# STM32U083 register map
File version: 0.2
CPU: CM0+ r0p1, little endian, MPU, no FPU, 4 interrupt priority bits
Registers are 32-bit, read-write, reset 0x0 unless marked. A register's access mark holds for its fields unless they carry their own. Offsets are from the block's base; [hi:lo] are bit positions; {n}, {i} and the like mark numbered series; 'fields as' and 'values as' point back to an identical list.

## AES — AES register block
Base 0x40026000
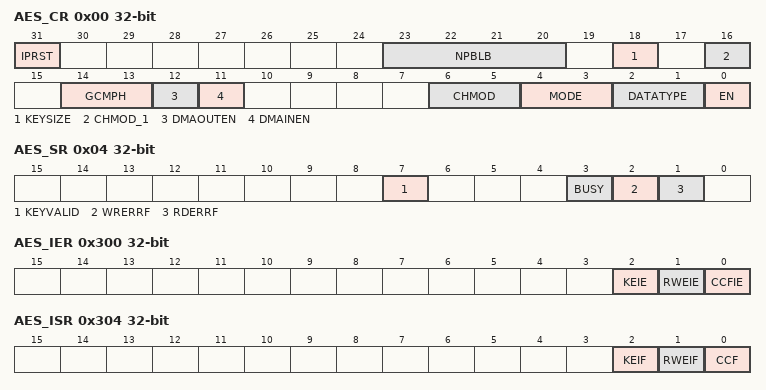
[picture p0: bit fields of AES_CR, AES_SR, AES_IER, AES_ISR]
0x00 AES_CR — AES control register
  [31] IPRST — AES peripheral software reset Setting the bit resets the AES peripheral, putting all registers to their default values, except the IPRST bit itself. Hence, any key-relative data are lost. For this reason, it is recommended to set the bit before handing over the AES to a less secure application. The bit must be kept low while writing any configuration registers.
  [23:20] NPBLB — Number of padding bytes in last block This padding information must be filled by software before processing the last block of GCM payload encryption or CCM payload decryption, otherwise authentication tag computation is incorrect. ...
    0=All bytes are valid (no padding); 1=Padding for the last LSB byte; 15=Padding for the 15 LSB bytes of last block
  [18] KEYSIZE — Key size selection This bitfield defines the key length in bits of the key used by AES. Attempts to write the bit are ignored when the EN is set before the write access and it is not cleared by that write access.
    0=128-bit; 1=256-bit
  [16] CHMOD_1 — CHMOD[2]
  [14:13] GCMPH — GCM or CCM phase selection This bitfield selects the phase, applicable only with GCM, GMAC or CCM chaining modes.
    0=Initialization phase; 1=Header phase; 2=Payload phase; 3=Final phase
  [12] DMAOUTEN — DMA output enable This bit enables automatic generation of DMA requests during the data phase, for outgoing data transfers from AES via DMA. Setting this bit is ignored when MODE[1:0] is at 0x1 (key derivation).
    0=Disable; 1=Enable
  [11] DMAINEN — DMA input enable This bit enables automatic generation of DMA requests during the data phase, for incoming data transfers to AES via DMA. Setting this bit is ignored when MODE[1:0] is at 0x1 (key derivation).
    0=Disable; 1=Enable
  [6:5] CHMOD — CHMOD[1:0]: Chaining mode This bitfield selects the AES chaining mode: others: Reserved Attempts to write the bitfield are ignored when EN is set before the write access and it is not cleared by that write access.
    0=Electronic codebook (ECB); 1=Cipher-block chaining (CBC); 2=Counter mode (CTR); 3=Galois counter mode (GCM) and Galois message authentication code (GMAC)
  [4:3] MODE — Operating mode This bitfield selects the AES operating mode: Attempts to write the bitfield are ignored when EN is set before the write access and it is not cleared by that write access.
    0=Encryption; 1=Key derivation (or key preparation), for ECB/CBC decryption only; 2=Decryption
  [2:1] DATATYPE — Data type This bitfield defines the format of data written in the AES_DINR register or read from the AES_DOUTR register, through selecting the mode of data swapping. This swapping is defined in Section121.4.14: AES data registers and data swapping. Attempts to write the bitfield are ignored when EN is set before the write access and it is not cleared by that write access.
    0=No swapping (32-bit data); 1=Half-word swapping (16-bit data); 2=Byte swapping (8-bit data); 3=Bit-level swapping
  [0] EN — Enable This bit enables/disables the AES peripheral. At any moment, clearing then setting the bit re-initializes the AES peripheral. This bit is automatically cleared by hardware upon the completion of the key preparation (MODE[1:0] at 0x1) and upon the completion of GCM/GMAC/CCM initialization phase. The bit cannot be set as long as KEYVALID1is cleared
    0=Disable; 1=Enable
0x04 AES_SR ro — AES status register
  [7] KEYVALID — Key valid flag This bit is set by hardware when the key of size defined by KEYSIZE is loaded in AES_KEYRx key registers. The EN bit can only be set when KEYVALID is set. The key must be written in the key registers in the correct sequence, otherwise the KEIF flag is set and KEYVALID remains cleared. If set, KEIF must be cleared through the AES_ICR register, otherwise KEYVALID cannot be set. See the KEIF flag description for more details. For further information on key loading, refer to Section121.4.15: AES key registers.
    0=Key not valid; 1=Key valid
  [3] BUSY — Busy This flag indicates whether AES is idle or busy. AES is flagged as idle when disabled (when EN is low) or when the last processing is completed. AES is flagged as busy when processing a block data, preparing a key (ECB or CBC decryption only). When GCM encryption is selected, this flag must be at zero before suspending current process to manage a higher-priority message.
    0=Idle; 1=Busy
  [2] WRERRF — Write error flag This bit is set when an unexpected write to the AES_DINR register occurred. When set WRERRF bit has no impact on the AES operations. The flag setting generates an interrupt if the RWEIE bit of the AES_IER register is set. The flag is cleared by setting the RWEIF bit of the AES_ICR register.
    0=No error; 1=Unexpected write to AES_DINR register occurred during computation or data output phase
  [1] RDERRF — Read error flag This bit is set when an unexpected read to the AES_DOUTR register occurred. When set RDERRF bit has no impact on the AES operations. The flag setting generates an interrupt if the RWEIE bit of the AES_IER register is set. The flag is cleared by setting the RWEIF bit of the AES_ICR register.
    0=No error; 1=Unexpected read to AES_DOUTR register occurred during computation or data input phase
0x08 AES_DINR wo — AES data input register
  [31:0] DIN — Data input A four-fold sequential write to this bitfield during the Input phase results in writing a complete 16-bytes block of input data to the AES peripheral. From the first to the fourth write, the corresponding data weights are [127:96], [95:64], [63:32], and [31:0]. Upon each write, the data from the 32-bit input buffer are handled by the data swap block according to the DATATYPE[1:0] bitfield, then written into the AES core 16-bytes input buffer. Reads return zero.
0x0C AES_DOUTR ro — AES data output register
  [31:0] DOUT — Data output This read-only bitfield fetches a 32-bit output buffer. A four-fold sequential read of this bitfield, upon the computation completion (CCF flag set), virtually reads a complete 16-byte block of output data from the AES peripheral. Before reaching the output buffer, the data produced by the AES core are handled by the data swap block according to the DATATYPE[1:0] bitfield. Data weights from the first to the fourth read operation are: [127:96], [95:64], [63:32], and [31:0].
0x10 AES_KEYR0 wo — AES key register 0
  [31:0] KEY — Cryptographic key, bits [31:0] These are bits [31:0] of the write-only bitfield KEY[255:0] AES encryption or decryption key, depending on the MODE[1:0] bitfield of the AES_CR register. Writes to AES_KEYRx registers are ignored when AES is enabled (EN bit set). A special writing sequence is required. In this sequence, any valid write to AES_KEYRx register clears the KEYVALID flag except for the sequence-completing write that sets it. Also refer to the description of the KEYVALID flag in the AES_SR register.
{0x10+4i} AES_KEYR{i} wo (i=1..3) — AES key register {i}
  [31:0] KEY — Cryptographic key, bits [{32i+31}:{32i}] Refer to the AES_KEYR0 register for description of the KEY[255:0] bitfield and for information relative to writing AES_KEYRx registers.
0x20 AES_IVR0 — AES initialization vector register 0
  [31:0] IVI — Initialization vector input, bits [31:0] AES_IVRx registers store the 128-bit initialization vector or the nonce, depending on the chaining mode selected. This value is updated by hardware after each computation round (when applicable). Write to this register is ignored when EN bit is set in AES_SR register
{0x20+4i} AES_IVR{i} (i=1..3) — AES initialization vector register {i}
  [31:0] IVI — Initialization vector input, bits [{32i+31}:{32i}] Refer to the AES_IVR0 register for description of the IVI[128:0] bitfield.
{0x20+4i} AES_KEYR{i} wo (i=4..7) — AES key register {i}
  fields as AES_KEYR1
{0x40+4i} AES_SUSPR{i} (i=0..7) — AES suspend registers
  [31:0] SUSP — Suspend data AES_SUSPRx registers contain the complete internal register states of the AES when the GCM, GMAC or CCM processing of the current task is suspended to process a higher-priority task. Refer to Section121.4.8: AES suspend and resume operations for more details. Read to this register returns zero when EN bit is cleared in AES_SR register. AES_SUSPRx registers are not used in other chaining modes than GCM, GMAC or CCM.
0x300 AES_IER — AES interrupt enable register
  [all] fields
    0=Disabled (masked); 1=Enabled (not masked)
  [2] KEIE — Key error interrupt enable This bit enables or disables (masks) the AES interrupt generation when KEIF (key error flag) is set.
  [1] RWEIE — Read or write error interrupt enable This bit enables or disables (masks) the AES interrupt generation when RWEIF (read and/or write error flag) is set.
  [0] CCFIE — Computation complete flag interrupt enable This bit enables or disables (masks) the AES interrupt generation when CCF (computation complete flag) is set.
0x304 AES_ISR ro — AES interrupt status register
  [2] KEIF — Key error interrupt flag This read-only bit is set by hardware when the key information fails to load into key registers. The flag setting generates an interrupt if the KEIE bit of the AES_IER register is set. The flag is cleared by setting the corresponding bit of the AES_ICR register. KEIF is raised upon any of the following events: AES_KEYRx register write does not respect the correct order. (For KEYSIZE1cleared, AES_KEYR0 then AES_KEYR1 then AES_KEYR2 then AES_KEYR3 register, or reverse. For KEYSIZE set, AES_KEYR0 then AES_KEYR1 then AES_KEYR2 then AES_KEYR3 then AES_KEYR4 then AES_KEYR5 then AES_KEYR6 then AES_KEYR7, or reverse). KEIF must be cleared by the application software, otherwise KEYVALID cannot be set.
    0=No key error detected; 1=Key information failed to load into key registers
  [1] RWEIF — Read or write error interrupt flag This read-only bit is set by hardware when a RDERRF or a WRERRF error flag is set in the AES_SR register. The flag setting generates an interrupt if the RWEIE bit of the AES_IER register is set. The flag is cleared by setting the corresponding bit of the AES_ICR register. The flags has no meaning when key derivation mode is selected. See the AES_SR register for details.
    0=No read or write error detected; 1=Read or write error detected
  [0] CCF — Computation complete flag This flag indicates whether the computation is completed. It is significant only when the DMAOUTEN bit is cleared, and it may stay high when DMAOUTEN is set. The flag setting generates an interrupt if the CCFIE bit of the AES_IER register is set. The flag is cleared by setting the corresponding bit of the AES_ICR register.
    0=Not completed; 1=Completed
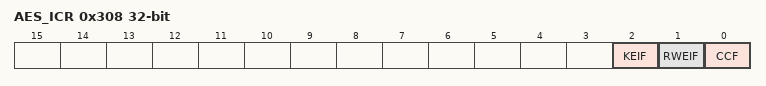
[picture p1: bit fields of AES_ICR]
0x308 AES_ICR wo — AES interrupt clear register
  [2] KEIF — Key error interrupt flag clear Setting this bit clears the KEIF status bit of the AES_ISR register.
  [1] RWEIF — Read or write error interrupt flag clear Setting this bit clears the RWEIF status bit of the AES_ISR register, and clears both RDERRF and WRERRF flags in the AES_SR register.
  [0] CCF — Computation complete flag clear Setting this bit clears the CCF status bit of the AES_ISR register.

## Notices in the file
Copyright (c) 2024 STMicroelectronics.
SPDX-License-Identifier: Apache-2.0
Licensed under the Apache License, Version 2.0 (the "License");
you may not use this file except in compliance with the License.
You may obtain a copy of the License at
http://www.apache.org/licenses/LICENSE-2.0
Unless required by applicable law or agreed to in writing, software
distributed under the License is distributed on an "AS IS" BASIS,
WITHOUT WARRANTIES OR CONDITIONS OF ANY KIND, either express or implied.
See the License for the specific language governing permissions and
limitations under the License.
